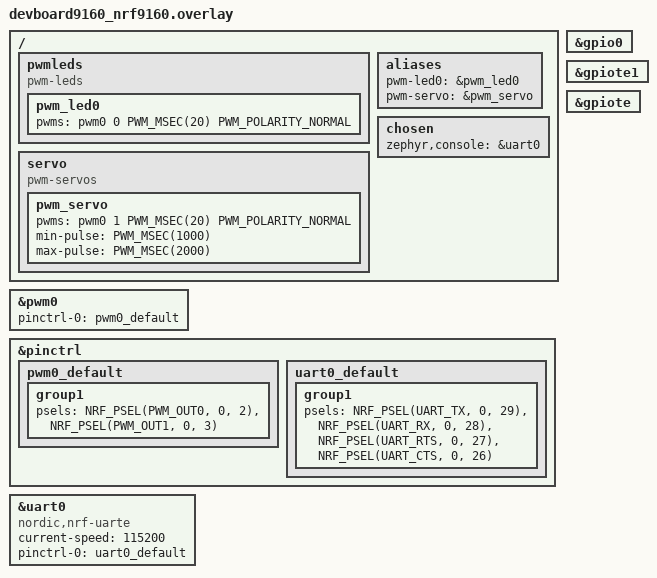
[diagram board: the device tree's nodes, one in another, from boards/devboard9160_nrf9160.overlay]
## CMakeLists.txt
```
# SPDX-License-Identifier: Apache-2.0

cmake_minimum_required(VERSION 3.20.0)


find_package(Zephyr REQUIRED HINTS $ENV{ZEPHYR_BASE})
project(pwm_led)

target_sources(app PRIVATE src/main.c)
```

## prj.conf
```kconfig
# nothing here

# Enable GPIO
CONFIG_GPIO=y

# Enable UART driver
CONFIG_SERIAL=y

# Enable console
CONFIG_CONSOLE=y
CONFIG_UART_CONSOLE=y

CONFIG_LOG_BACKEND_UART=y

CONFIG_LOG=y
# CONFIG_PARTITION_MANAGER_ENABLED=y
CONFIG_LOG_FRONTEND_OPT_API=y
CONFIG_LOG_BACKEND_SHOW_COLOR=y
CONFIG_LOG_INFO_COLOR_GREEN=y
CONFIG_LOG_DBG_COLOR_BLUE=y
CONFIG_LOG_OUTPUT_FORMAT_LINUX_TIMESTAMP=y
CONFIG_PWM=y
CONFIG_PWM_LOG_LEVEL_DBG=y
CONFIG_LED=y
CONFIG_LED_PWM=y
```

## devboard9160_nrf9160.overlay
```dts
// To get started, press Ctrl+Space to bring up the completion menu and view the available nodes.

// You can also use the buttons in the sidebar to perform actions on nodes.
// Actions currently available include:

// * Enabling / disabling the node
// * Adding the bus to a bus
// * Removing the node
// * Connecting ADC channels

// For more help, browse the DeviceTree documentation at https://docs.zephyrproject.org/latest/guides/dts/index.html
// You can also visit the nRF DeviceTree extension documentation at https://docs.nordicsemi.com/bundle/nrf-connect-vscode/page/guides/ncs_configure_app.html#devicetree-support-in-the-extension

&pwm0 {
	status = "okay";
	pinctrl-0 = <&pwm0_default>;
	pinctrl-names = "default";
};

&gpio0 {
	status = "okay";
};

&gpiote1 {
	status = "okay";
};

&gpiote {
	status = "okay";
};

&pinctrl {
	pwm0_default: pwm0_default {
		group1 {
			psels = <NRF_PSEL(PWM_OUT0, 0, 2)>;
		};
	};

	uart0_default: uart0_default {
		group1 {
			psels = <NRF_PSEL(UART_TX, 0, 29)>,
					<NRF_PSEL(UART_RX, 0, 28)>,
					<NRF_PSEL(UART_RTS, 0, 27)>,
					<NRF_PSEL(UART_CTS, 0, 26)>;
		};
	};
};

/ {
	pwmleds {
		compatible = "pwm-leds";
		 pwm_led0: pwm_led0 {
			pwms = <&pwm0 0 PWM_MSEC(20) PWM_POLARITY_NORMAL>;
		};
	};

	aliases {
		pwm-led0 = &pwm_led0;
	};

	chosen {
		zephyr,console = &uart0;
	};
};

&uart0 {
	status = "okay";
	current-speed = <115200>;
	pinctrl-0 = <&uart0_default>;
	pinctrl-names = "default";
	compatible = "nordic,nrf-uarte";
};
```

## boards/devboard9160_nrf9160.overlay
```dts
// To get started, press Ctrl+Space to bring up the completion menu and view the available nodes.

// You can also use the buttons in the sidebar to perform actions on nodes.
// Actions currently available include:

// * Enabling / disabling the node
// * Adding the bus to a bus
// * Removing the node
// * Connecting ADC channels

// For more help, browse the DeviceTree documentation at https://docs.zephyrproject.org/latest/guides/dts/index.html
// You can also visit the nRF DeviceTree extension documentation at https://docs.nordicsemi.com/bundle/nrf-connect-vscode/page/guides/ncs_configure_app.html#devicetree-support-in-the-extension

&pwm0 {
	status = "okay";
	pinctrl-0 = <&pwm0_default>;
	pinctrl-names = "default";
};

&gpio0 {
	status = "okay";
};

&gpiote1 {
	status = "okay";
};

&gpiote {
	status = "okay";
};

&pinctrl {
	pwm0_default: pwm0_default {
		group1 {
			psels = <NRF_PSEL(PWM_OUT0, 0, 2)>, <NRF_PSEL(PWM_OUT1, 0, 3)>;
		};
	};

	uart0_default: uart0_default {
		group1 {
			psels = <NRF_PSEL(UART_TX, 0, 29)>,
					<NRF_PSEL(UART_RX, 0, 28)>,
					<NRF_PSEL(UART_RTS, 0, 27)>,
					<NRF_PSEL(UART_CTS, 0, 26)>;
		};
	};
};

/ {
	pwmleds {
		compatible = "pwm-leds";
		 pwm_led0: pwm_led0 {
			pwms = <&pwm0 0 PWM_MSEC(20) PWM_POLARITY_NORMAL>;
		};
	};

	servo: servo {
		compatible = "pwm-servos";
		pwm_servo: pwm_servo{
			pwms = <&pwm0 1 PWM_MSEC(20) PWM_POLARITY_NORMAL>;
			min-pulse = <PWM_MSEC(1000)>;
			max-pulse = <PWM_MSEC(2000)>;
		};
		
	};

	aliases {
		pwm-led0 = &pwm_led0;
		pwm-servo = &pwm_servo;
	};

	chosen {
		zephyr,console = &uart0;
	};

	
};

&uart0 {
	status = "okay";
	current-speed = <115200>;
	pinctrl-0 = <&uart0_default>;
	pinctrl-names = "default";
	compatible = "nordic,nrf-uarte";
};
```

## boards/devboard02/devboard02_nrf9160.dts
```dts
/*
 * Copyright (c) 2018-2020 Nordic Semiconductor ASA
 *
 * SPDX-License-Identifier: Apache-2.0
 */

/dts-v1/;
#include <nordic/nrf9160_sica.dtsi>
#include "devboard02_nrf9160_common.dtsi"

/ {
	chosen {
		zephyr,sram = &sram0_s;
		zephyr,flash = &flash0;
		zephyr,code-partition = &slot0_partition;
		zephyr,sram-secure-partition = &sram0_s;
		zephyr,sram-non-secure-partition = &sram0_ns;
	};
};
```

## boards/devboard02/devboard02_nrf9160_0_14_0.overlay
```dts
/*
 * Copyright (c) 2021 Nordic Semiconductor ASA
 *
 * SPDX-License-Identifier: Apache-2.0
 */

#include "devboard02_nrf9160_common_0_14_0.dtsi"
```

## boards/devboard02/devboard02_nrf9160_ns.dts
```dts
/*
 * Copyright (c) 2018-2020 Nordic Semiconductor ASA
 *
 * SPDX-License-Identifier: Apache-2.0
 */

/dts-v1/;
#include <nordic/nrf9160ns_sica.dtsi>
#include "devboard02_nrf9160_common.dtsi"

/ {
	chosen {
		zephyr,flash = &flash0;
		zephyr,sram = &sram0_ns;
		zephyr,code-partition = &slot0_ns_partition;
	};
};

/* Disable UART1, because it is used by default in TF-M */
&uart1 {
	status = "disabled";
};
```

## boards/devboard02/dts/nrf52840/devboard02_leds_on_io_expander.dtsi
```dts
/*
 * Copyright (c) 2021 Nordic Semiconductor ASA
 *
 * SPDX-License-Identifier: Apache-2.0
 */

/* NOTE: this feature is only available in DevBoard02 v0.14.0 or later. */

&led1_pin_routing {
	status = "disabled";
};

&led2_pin_routing {
	status = "disabled";
};

&led3_pin_routing {
	status = "disabled";
};

&led4_pin_routing {
	status = "disabled";
};

&io_expander_pins_routing {
	status = "okay";
};
```

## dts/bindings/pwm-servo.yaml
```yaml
description: PWM-driven servo motor.

compatible: "pwm-servos"

include: base.yaml

child-binding:
  properties:
    pwms:
      required: true
      type: phandle-array
      description: PWM channel configurationspecifier driving the servo motor.

    min-pulse:
      required: true
      type: int
      description: Minimum pulse width (nanoseconds).

    max-pulse:
      required: true
      type: int
      description: Maximum pulse width (nanoseconds).
```

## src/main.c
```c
/*
 * Copyright (c) 2012-2014 Wind River Systems, Inc.
 *
 * SPDX-License-Identifier: Apache-2.0
 */

#include <stdio.h>
#include <zephyr/device.h>
#include <zephyr/drivers/pwm.h>
#include <zephyr/kernel.h>

#define PWM_LED0_NODE DT_ALIAS(pwm_led0)
#define PWM_SERVO_NODE DT_ALIAS(pwm_servo)

//Use DT_PROP() to obtain the minimum and maximum duty cycle */
#define PWM_SERVO_MIN_DUTY_CYCLE    DT_PROP(PWM_SERVO_NODE, min_pulse)
#define PWM_SERVO_MAX_DUTY_CYCLE    DT_PROP(PWM_SERVO_NODE, max_pulse)

#define PWM_PERIOD_MS 20
#define PWM_DUTY_CYCLE_MS 1
#define SLEEP_TIME_MS 20

static struct pwm_dt_spec pwm_led0 = PWM_DT_SPEC_GET(PWM_LED0_NODE);
static struct pwm_dt_spec pwm_servo = PWM_DT_SPEC_GET(PWM_SERVO_NODE);

int main(void)
{
	int rc;
	rc = pwm_is_ready_dt(&pwm_led0);
	printf("Starting the application\r\n");
	if(rc < 0)
	{
		printf("Error: PWM device %s is not ready\n", pwm_led0.dev->name);
		return 1;
	}

	rc = pwm_is_ready_dt(&pwm_servo);
	if(rc < 0)
	{
		printf("Error: PWM device %s is not ready\n", pwm_servo.dev->name);
		return 1;
	}

	// below code will provide the glow effect on the LED
	do
	{

		int duty_cycle = 0;
		for (int index = 0; index < 100; index += 4)
		{
			duty_cycle = (index * PWM_PERIOD_MS)/100;
			rc = pwm_set_dt(&pwm_led0, PWM_MSEC(PWM_PERIOD_MS), PWM_MSEC(duty_cycle));
			if (rc < 0)
			{
				printf("Error: PWM device %s is not ready\n", pwm_led0.dev->name);
				return 1;
			}
			k_msleep(SLEEP_TIME_MS);
		}

		for (int index = 100; index > 0; index -= 4)
		{
			duty_cycle = (index * PWM_PERIOD_MS)/100;
			rc = pwm_set_dt(&pwm_led0, PWM_MSEC(PWM_PERIOD_MS), PWM_MSEC(duty_cycle));
			if (rc < 0)
			{
				printf("Error: PWM device %s is not ready\n", pwm_led0.dev->name);
				return 1;
			}
			k_msleep(SLEEP_TIME_MS);
		}
	} while (1);
	

	printf("PWM device %s is ready\n", pwm_led0.dev->name);

	return 0;
}
```
